# haltium_application register map
Vendor: Nordic Semiconductor; Series: nRFHaltium; File version: 1
CPU: CM33 r0p4, little endian, MPU, FPU, 3 interrupt priority bits, 480 interrupts
Registers are 32-bit, read-write, reset 0x0 unless marked. A register's access mark holds for its fields unless they carry their own. Offsets are from the block's base; [hi:lo] are bit positions; lines under a group give offsets from that group; 'fields as' and 'values as' point back to an identical list.

## GLOBAL_EASYVDMA_NS — Vector-based DMA.
Base 0x5F9E0000
0x00 TASKS_START wo — Start operation.
  [0] TASKS_START
    1=Trigger task
0x04 TASKS_STOP wo — Stop operation.
  [0] TASKS_STOP
    1=Trigger task
0x08 TASKS_RESET wo — Reset operation.
  [0] TASKS_RESET
    1=Trigger task
0x100 EVENTS_LISTDONE — Unspecified
  [0] EVENTS_LISTDONE
    0=NotGenerated (Event not generated); 1=Generated (Event generated)
0x104 EVENTS_LISTPARTDONE — Unspecified
  [0] EVENTS_LISTPARTDONE
    values as EVENTS_LISTDONE.EVENTS_LISTDONE
0x108 EVENTS_SELECTJOBDONE — Unspecified
  [0] EVENTS_SELECTJOBDONE
    values as EVENTS_LISTDONE.EVENTS_LISTDONE
0x10C EVENTS_JOBRECEIVED — Unspecified
  [0] EVENTS_JOBRECEIVED
    values as EVENTS_LISTDONE.EVENTS_LISTDONE
0x110 EVENTS_JOBDONE — Unspecified
  [0] EVENTS_JOBDONE
    values as EVENTS_LISTDONE.EVENTS_LISTDONE
0x114 EVENTS_ERROR — Unspecified
  [0] EVENTS_ERROR
    values as EVENTS_LISTDONE.EVENTS_LISTDONE
0x118 EVENTS_STOP — Unspecified
  [0] EVENTS_STOP
    values as EVENTS_LISTDONE.EVENTS_LISTDONE
0x11C EVENTS_RESET — Unspecified
  [0] EVENTS_RESET
    values as EVENTS_LISTDONE.EVENTS_LISTDONE
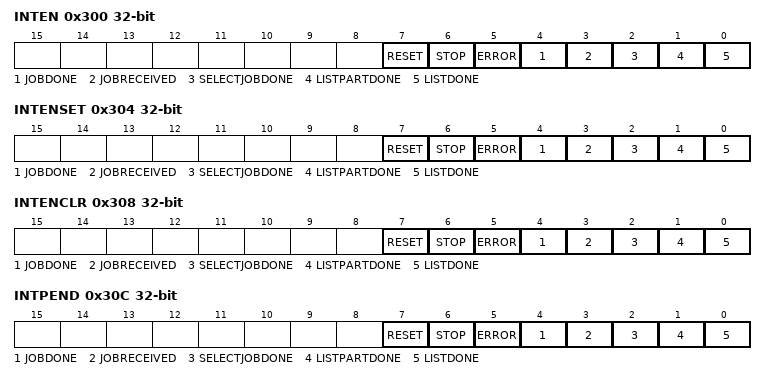
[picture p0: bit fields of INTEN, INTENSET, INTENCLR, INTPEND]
0x300 INTEN — Enable or disable interrupt
  [all] fields
    0=Disabled; 1=Enabled
  [7] RESET — Enable or disable interrupt for event RESET
  [6] STOP — Enable or disable interrupt for event STOP
  [5] ERROR — Enable or disable interrupt for event ERROR
  [4] JOBDONE — Enable or disable interrupt for event JOBDONE
  [3] JOBRECEIVED — Enable or disable interrupt for event JOBRECEIVED
  [2] SELECTJOBDONE — Enable or disable interrupt for event SELECTJOBDONE
  [1] LISTPARTDONE — Enable or disable interrupt for event LISTPARTDONE
  [0] LISTDONE — Enable or disable interrupt for event LISTDONE
0x304 INTENSET — Enable interrupt
  [all] fields
    on read: 0=Disabled (Read: Disabled); 1=Enabled (Read: Enabled) | on write: 1=Set (Enable)
  [7] RESET — Write '1' to enable interrupt for event RESET
  [6] STOP — Write '1' to enable interrupt for event STOP
  [5] ERROR — Write '1' to enable interrupt for event ERROR
  [4] JOBDONE — Write '1' to enable interrupt for event JOBDONE
  [3] JOBRECEIVED — Write '1' to enable interrupt for event JOBRECEIVED
  [2] SELECTJOBDONE — Write '1' to enable interrupt for event SELECTJOBDONE
  [1] LISTPARTDONE — Write '1' to enable interrupt for event LISTPARTDONE
  [0] LISTDONE — Write '1' to enable interrupt for event LISTDONE
0x308 INTENCLR — Disable interrupt
  [all] fields
    on read: 0=Disabled (Read: Disabled); 1=Enabled (Read: Enabled) | on write: 1=Clear (Disable)
  [7] RESET — Write '1' to disable interrupt for event RESET
  [6] STOP — Write '1' to disable interrupt for event STOP
  [5] ERROR — Write '1' to disable interrupt for event ERROR
  [4] JOBDONE — Write '1' to disable interrupt for event JOBDONE
  [3] JOBRECEIVED — Write '1' to disable interrupt for event JOBRECEIVED
  [2] SELECTJOBDONE — Write '1' to disable interrupt for event SELECTJOBDONE
  [1] LISTPARTDONE — Write '1' to disable interrupt for event LISTPARTDONE
  [0] LISTDONE — Write '1' to disable interrupt for event LISTDONE
0x30C INTPEND ro — Pending interrupts
  [all] fields
    on read: 0=NotPending (Read: Not pending); 1=Pending (Read: Pending)
  [7] RESET — Read pending status of interrupt for event RESET
  [6] STOP — Read pending status of interrupt for event STOP
  [5] ERROR — Read pending status of interrupt for event ERROR
  [4] JOBDONE — Read pending status of interrupt for event JOBDONE
  [3] JOBRECEIVED — Read pending status of interrupt for event JOBRECEIVED
  [2] SELECTJOBDONE — Read pending status of interrupt for event SELECTJOBDONE
  [1] LISTPARTDONE — Read pending status of interrupt for event LISTPARTDONE
  [0] LISTDONE — Read pending status of interrupt for event LISTDONE
0x400 STATUS group — EasyVDMA status registers.
  0x00 BYTECOUNT ro — Number of bytes sent or received during processing of current descriptor list
  0x04 ATTRIBUTE ro — Latest data attribute being processed.
    [6:0] ATTRIBUTE
  0x08 ADDRESS ro — Latest address being processed.
  0x0C JOBCOUNT ro — Number of jobs completed in current descriptor list.
  0x10 BUSERROR ro — AXI bus error status.
    [2:0] BUSERROR — AXI bus error type
      0=NoError (There are no errors.); 1=ReadSlaveError (Read error generated by AXI slave.); 2=ReadDecodeError (Read error generated by interconnect.); 3=WriteSlaveError (Write error generated by AXI slave.); 4=WriteDecodeError (Write error generated by interconnect.)
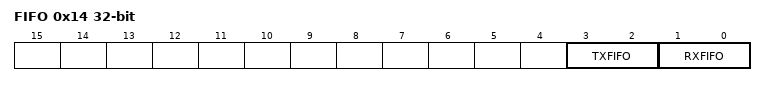
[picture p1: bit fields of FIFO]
  0x14 FIFO ro — Data fifo status.
    [3:2] TXFIFO — Peripheral-to-Memory direction data fifo status
      0=Empty (Fifo is empty.); 1=AlmostFull (Fifo is almost full.); 2=Full (Fifo is full.)
    [1:0] RXFIFO — Memory-to-Peripheral direction data fifo status
      values as TXFIFO
  0x18 ACTIVE ro — DMA activity state.
    [0] ACTIVE
      0=Idle (DMA is in idle state.); 1=Active (Data is being transferred.)
0x500 ENABLE — Enable the EasyVDMA peripheral.
  [0] ENABLE — Enable or disable EasyVDMA
    0=Disabled (Disable EasyVDMA); 1=Enabled (Enable EasyVDMA)
0x504 CONFIG group — General config registers
  0x00 BUFFERFILL — Data to be used when data is sent with bufferFill-attribute
    [7:0] BUFFERFILL
  0x04 LISTPTR — Start address of descriptor list
  0x08 LISTPARTTHRESH — Threshold value for generating event when descriptor list is partially completed. Value is number of jobs.
    [15:0] LISTPARTTHRESH — Threshold value.
  0x0C DESCRIPTORPREFETCHLEN — This configures how many job descriptors are loaded from memory and registered locally before processing.
    [2:0] DESCRIPTORPREFETCHLEN — Job descriptor buffer size
  0x10 FIFODEPTH — This configures the depth of RX and TX data fifos.
    [2:0] FIFODEPTH — Fifo depth in DMA_DW units.

## Notices in the file
Copyright (c) 2010 - 2020, Nordic Semiconductor ASA
All rights reserved.
Redistribution and use in source and binary forms, with or without modification,
are permitted provided that the following conditions are met:
1. Redistributions of source code must retain the above copyright notice, this
list of conditions and the following disclaimer.
2. Redistributions in binary form, except as embedded into a Nordic
Semiconductor ASA integrated circuit in a product or a software update for
such product, must reproduce the above copyright notice, this list of
conditions and the following disclaimer in the documentation and/or other
materials provided with the distribution.
3. Neither the name of Nordic Semiconductor ASA nor the names of its
contributors may be used to endorse or promote products derived from this
software without specific prior written permission.
4. This software, with or without modification, must only be used with a
Nordic Semiconductor ASA integrated circuit.
5. Any software provided in binary form under this license must not be reverse
engineered, decompiled, modified and/or disassembled.
THIS SOFTWARE IS PROVIDED BY NORDIC SEMICONDUCTOR ASA "AS IS" AND ANY EXPRESS
OR IMPLIED WARRANTIES, INCLUDING, BUT NOT LIMITED TO, THE IMPLIED WARRANTIES
OF MERCHANTABILITY, NONINFRINGEMENT, AND FITNESS FOR A PARTICULAR PURPOSE ARE
DISCLAIMED. IN NO EVENT SHALL NORDIC SEMICONDUCTOR ASA OR CONTRIBUTORS BE
LIABLE FOR ANY DIRECT, INDIRECT, INCIDENTAL, SPECIAL, EXEMPLARY, OR
CONSEQUENTIAL DAMAGES (INCLUDING, BUT NOT LIMITED TO, PROCUREMENT OF SUBSTITUTE
GOODS OR SERVICES; LOSS OF USE, DATA, OR PROFITS; OR BUSINESS INTERRUPTION)
HOWEVER CAUSED AND ON ANY THEORY OF LIABILITY, WHETHER IN CONTRACT, STRICT
LIABILITY, OR TORT (INCLUDING NEGLIGENCE OR OTHERWISE) ARISING IN ANY WAY OUT
OF THE USE OF THIS SOFTWARE, EVEN IF ADVISED OF THE POSSIBILITY OF SUCH DAMAGE.
